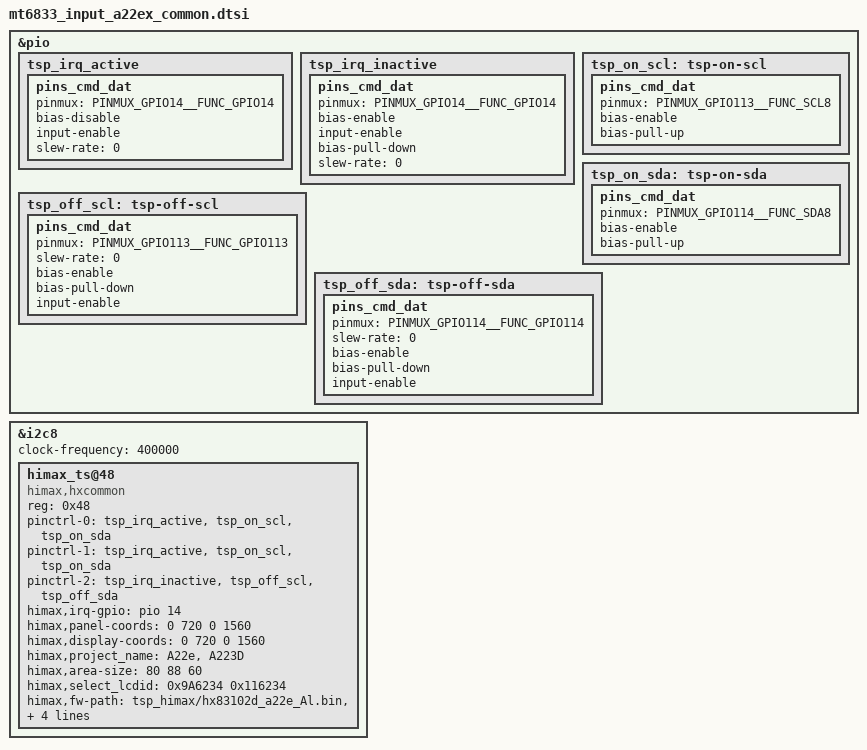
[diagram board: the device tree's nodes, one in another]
/*
 * SAMSUNG Input Device Tree Source
 *
 * Copyright (c) Samsung Electronics Co., Ltd.
 *		http://www.samsung.com
 *
 * This program is free software; you can redistribute it and/or modify
 * it under the terms of the GNU General Public License version 2 as
 * published by the Free Software Foundation.
 */

&pio {
	tsp_irq_active: tsp_irq_active {
		pins_cmd_dat {
			pinmux = <PINMUX_GPIO14__FUNC_GPIO14>;
			bias-disable;
			input-enable;
			slew-rate = <0>;
		};
	};
	tsp_irq_inactive: tsp_irq_inactive {
		pins_cmd_dat {
			pinmux = <PINMUX_GPIO14__FUNC_GPIO14>;
			bias-enable;
			input-enable;
			bias-pull-down;
			slew-rate = <0>;
		};
	};
	tsp_on_scl: tsp-on-scl {
		pins_cmd_dat{
			pinmux = <PINMUX_GPIO113__FUNC_SCL8>;
			bias-enable;
			bias-pull-up;
		};
	};
	tsp_on_sda: tsp-on-sda {
		pins_cmd_dat{
			pinmux = <PINMUX_GPIO114__FUNC_SDA8>;
			bias-enable;
			bias-pull-up;
		};
	};
	tsp_off_scl: tsp-off-scl {
		pins_cmd_dat{
			pinmux = <PINMUX_GPIO113__FUNC_GPIO113>;
			slew-rate = <0>;
			bias-enable;
			bias-pull-down;
			input-enable;
		};
	};
	tsp_off_sda: tsp-off-sda {
		pins_cmd_dat{
			pinmux = <PINMUX_GPIO114__FUNC_GPIO114>;
			slew-rate = <0>;
			bias-enable;
			bias-pull-down;
			input-enable;
		};
	};
};

&i2c8 {
	status = "okay";
	clock-frequency = <400000>;

	himax_ts@48 {
		compatible = "himax,hxcommon";
		reg = <0x48>;
		pinctrl-names = "default","pins_on_state", "pins_off_state";
		pinctrl-0 = <&tsp_irq_active &tsp_on_scl &tsp_on_sda>;
		pinctrl-1 = <&tsp_irq_active &tsp_on_scl &tsp_on_sda>;
		pinctrl-2 = <&tsp_irq_inactive &tsp_off_scl &tsp_off_sda>;
		himax,irq-gpio = <&pio 14 0>;
		himax,panel-coords = <0 720 0 1560>;
		himax,display-coords = <0 720 0 1560>;
		himax,project_name = "A22e", "A223D";
		himax,area-size = <80 88 60>; /* indicator: using notch: 80px navigator:48dp~88px edge:60px | dpi:294*/
		himax,select_lcdid = <0x9A6234 0x116234>;
		himax,fw-path = "tsp_himax/hx83102d_a22e_Al.bin", "tsp_himax/hx83102d_a22e_Cu.bin";
		report_type = <1>;
		himax,factory_item_version = <2>;
		himax,enable_sysinput_enabled;
		};
};
